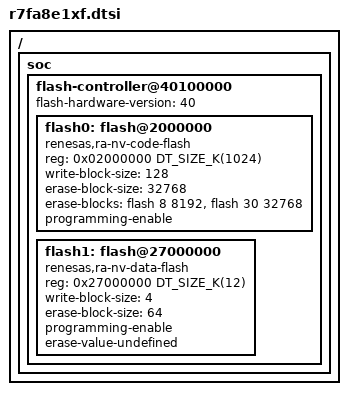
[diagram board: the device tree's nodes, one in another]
/*
 * Copyright (c) 2026 Renesas Electronics Corporation
 *
 * SPDX-License-Identifier: Apache-2.0
 */

/ {
	soc {
		flash-controller@40100000 {
			flash-hardware-version = <40>;
			#erase-block-cells = <2>;

			flash0: flash@2000000 {
				compatible = "renesas,ra-nv-code-flash";
				reg = <0x02000000 DT_SIZE_K(1024)>;
				ranges = <0x0 0x02000000 DT_SIZE_K(1024)>;
				#address-cells = <1>;
				#size-cells = <1>;
				write-block-size = <128>;
				erase-block-size = <32768>;
				erase-blocks = <&flash 8 8192>, <&flash 30 32768>;
				programming-enable;
			};

			flash1: flash@27000000 {
				compatible = "renesas,ra-nv-data-flash";
				reg = <0x27000000 DT_SIZE_K(12)>;
				ranges = <0x0 0x27000000 DT_SIZE_K(12)>;
				#address-cells = <1>;
				#size-cells = <1>;
				write-block-size = <4>;
				erase-block-size = <64>;
				programming-enable;
				erase-value-undefined;
			};
		};
	};
};
